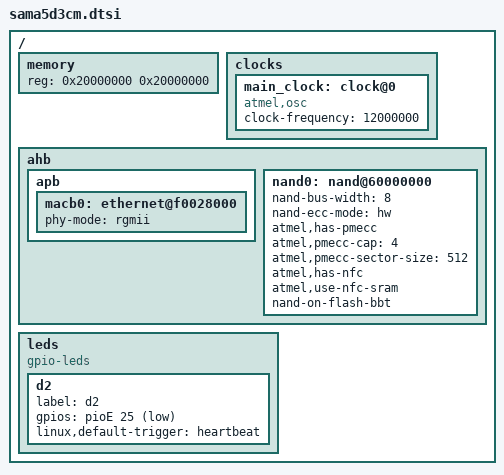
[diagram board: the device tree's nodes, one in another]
/*
 * sama5d3cm.dtsi - Device Tree Include file for SAMA5D3x CPU Module
 *
 *  Copyright (C) 2012 Atmel,
 *                2012 Ludovic Desroches <ludovic.desroches@atmel.com>
 *
 * Licensed under GPLv2 or later.
 */
/include/ "sama5d3.dtsi"

/ {
	memory {
		reg = <0x20000000 0x20000000>;
	};

	clocks {
		#address-cells = <1>;
		#size-cells = <1>;
		ranges;

		main_clock: clock@0 {
			compatible = "atmel,osc", "fixed-clock";
			clock-frequency = <12000000>;
		};
	};

	ahb {
		apb {
			macb0: ethernet@f0028000 {
				phy-mode = "rgmii";
			};
		};

		nand0: nand@60000000 {
			nand-bus-width = <8>;
			nand-ecc-mode = "hw";
			atmel,has-pmecc;
			atmel,pmecc-cap = <4>;
			atmel,pmecc-sector-size = <512>;
			atmel,has-nfc;
			atmel,use-nfc-sram;
			nand-on-flash-bbt;
			status = "okay";
		};
	};

	leds {
		compatible = "gpio-leds";

		d2 {
			label = "d2";
			gpios = <&pioE 25 1>;	/* PE25, conflicts with A25, RXD2 */
			linux,default-trigger = "heartbeat";
		};
	};
};
